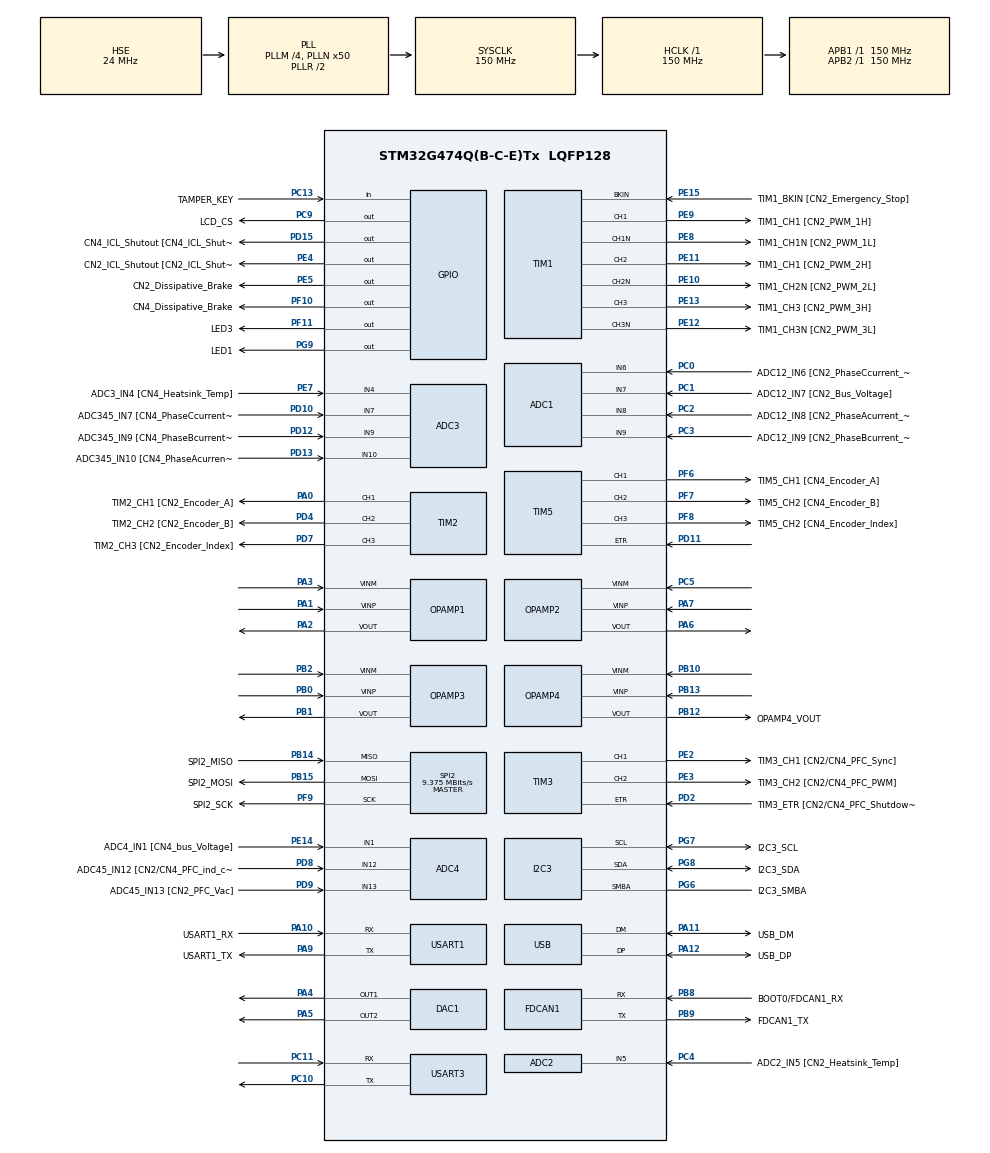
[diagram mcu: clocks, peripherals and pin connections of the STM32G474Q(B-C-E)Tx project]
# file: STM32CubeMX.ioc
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ADC1.Channel-7\#ChannelRegularConversion=ADC_CHANNEL_7
ADC1.NbrOfConversionFlag=1
ADC1.OffsetNumber-7\#ChannelRegularConversion=ADC_OFFSET_NONE
ADC1.Rank-7\#ChannelRegularConversion=1
ADC1.SamplingTime-7\#ChannelRegularConversion=ADC_SAMPLETIME_2CYCLES_5
ADC1.master=1
ADC2.Channel-0\#ChannelRegularConversion=ADC_CHANNEL_5
ADC2.NbrOfConversionFlag=1
ADC2.OffsetNumber-0\#ChannelRegularConversion=ADC_OFFSET_NONE
ADC2.Rank-0\#ChannelRegularConversion=1
ADC2.SamplingTime-0\#ChannelRegularConversion=ADC_SAMPLETIME_2CYCLES_5
ADC3.Channel-0\#ChannelRegularConversion=ADC_CHANNEL_9
ADC3.NbrOfConversionFlag=1
ADC3.OffsetNumber-0\#ChannelRegularConversion=ADC_OFFSET_NONE
ADC3.Rank-0\#ChannelRegularConversion=1
ADC3.SamplingTime-0\#ChannelRegularConversion=ADC_SAMPLETIME_2CYCLES_5
ADC3.master=1
ADC4.Channel-0\#ChannelRegularConversion=ADC_CHANNEL_12
ADC4.NbrOfConversionFlag=1
ADC4.OffsetNumber-0\#ChannelRegularConversion=ADC_OFFSET_NONE
ADC4.Rank-0\#ChannelRegularConversion=1
ADC4.SamplingTime-0\#ChannelRegularConversion=ADC_SAMPLETIME_2CYCLES_5
DAC1.DAC_Channel-DAC_OUT2=DAC_CHANNEL_2
FDCAN1.CalculateBaudRateNominal=3125000
FDCAN1.CalculateTimeBitNominal=320
FDCAN1.CalculateTimeQuantumNominal=106.66666666666667
I2C3.Timeout=0x00008727
I2C3.Timing=0x30D293D6
Mcu.Family=STM32G4
Mcu.Name=STM32G474Q(B-C-E)Tx
Mcu.Package=LQFP128
NVIC.PriorityGroup=NVIC_PRIORITYGROUP_4
NVIC.TIM20_UP_IRQn=true\:15\:0\:false\:false\:true\:false\:true\:true
NVIC.TimeBase=TIM20_UP_IRQn
NVIC.TimeBaseIP=TIM20
NVIC.USART1_IRQn=true\:8\:0\:true\:false\:true\:true\:true\:true
NVIC.USART3_IRQn=true\:8\:0\:true\:false\:true\:true\:true\:true
NVIC.USB_HP_IRQn=true\:8\:0\:true\:false\:true\:true\:true\:true
NVIC.USB_LP_IRQn=true\:8\:0\:true\:false\:true\:true\:true\:true
PA0.GPIO_Label=TIM2_CH1 [CN2_Encoder_A]
PA0.Signal=S_TIM2_CH1
PA1.Mode=Standalone
PA1.Signal=OPAMP1_VINP
PA10.GPIO_Label=USART1_RX
PA10.GPIO_Speed=GPIO_SPEED_FREQ_VERY_HIGH
PA10.Mode=Asynchronous
PA10.Signal=USART1_RX
PA11.GPIO_Label=USB_DM
PA11.Mode=Device
PA11.Signal=USB_DM
PA12.GPIO_Label=USB_DP
PA12.Mode=Device
PA12.Signal=USB_DP
PA13.GPIO_Label=JTMS-SWDIO
PA13.Mode=JTAG_5_pins
PA13.Signal=SYS_JTMS-SWDIO
PA14.GPIO_Label=JTCK-SWCLK
PA14.Mode=JTAG_5_pins
PA14.Signal=SYS_JTCK-SWCLK
PA15.Mode=JTAG_5_pins
PA15.Signal=SYS_JTDI
PA2.Mode=Standalone
PA2.Signal=OPAMP1_VOUT
PA3.Mode=Standalone
PA3.Signal=OPAMP1_VINM
PA4.Signal=COMP_DAC11_group
PA5.Signal=COMP_DAC12_group
PA6.Mode=Standalone
PA6.Signal=OPAMP2_VOUT
PA7.Mode=Standalone
PA7.Signal=OPAMP2_VINP
PA9.GPIO_Label=USART1_TX
PA9.GPIO_Speed=GPIO_SPEED_FREQ_VERY_HIGH
PA9.Mode=Asynchronous
PA9.Signal=USART1_TX
PB0.Mode=Standalone
PB0.Signal=OPAMP3_VINP
PB1.Mode=Standalone
PB1.Signal=OPAMP3_VOUT
PB10.Mode=Standalone
PB10.Signal=OPAMP4_VINM
PB12.GPIO_Label=OPAMP4_VOUT
PB12.Mode=Standalone
PB12.Signal=OPAMP4_VOUT
PB13.Mode=Standalone
PB13.Signal=OPAMP4_VINP
PB14.GPIO_Label=SPI2_MISO
PB14.Mode=Full_Duplex_Master
PB14.Signal=SPI2_MISO
PB15.GPIO_Label=SPI2_MOSI
PB15.Mode=Full_Duplex_Master
PB15.Signal=SPI2_MOSI
PB2.Mode=Standalone
PB2.Signal=OPAMP3_VINM
PB3.GPIO_Label=JTDO-SWO
PB3.Mode=JTAG_5_pins
PB3.Signal=SYS_JTDO-SWO
PB4.GPIO_Label=JTRST/PD_CC2
PB4.Mode=JTAG_5_pins
PB4.Signal=SYS_JTRST
PB8-BOOT0.GPIO_Label=BOOT0/FDCAN1_RX
PB8-BOOT0.Mode=FDCAN_Activate
PB8-BOOT0.Signal=FDCAN1_RX
PB9.GPIO_Label=FDCAN1_TX
PB9.Mode=FDCAN_Activate
PB9.Signal=FDCAN1_TX
PC0.GPIO_Label=ADC12_IN6 [CN2_PhaseCcurrent_plus]
PC0.Signal=SharedAnalog_PC0
PC1.GPIO_Label=ADC12_IN7 [CN2_Bus_Voltage]
PC1.Signal=SharedAnalog_PC1
PC10.GPIO_Speed=GPIO_SPEED_FREQ_VERY_HIGH
PC10.Mode=Asynchronous
PC10.Signal=USART3_TX
PC11.GPIO_Speed=GPIO_SPEED_FREQ_VERY_HIGH
PC11.Mode=Asynchronous
PC11.Signal=USART3_RX
PC13.GPIO_Label=TAMPER_KEY
PC13.Signal=GPIO_Input
PC14-OSC32_IN.GPIO_Label=PC14-OSC32_IN
PC14-OSC32_IN.Mode=LSE-External-Oscillator
PC14-OSC32_IN.Signal=RCC_OSC32_IN
PC15-OSC32_OUT.GPIO_Label=PC15-OSC32_OUT
PC15-OSC32_OUT.Mode=LSE-External-Oscillator
PC15-OSC32_OUT.Signal=RCC_OSC32_OUT
PC2.GPIO_Label=ADC12_IN8 [CN2_PhaseAcurrent_plus]
PC2.Signal=SharedAnalog_PC2
PC3.GPIO_Label=ADC12_IN9 [CN2_PhaseBcurrent_plus]
PC3.Signal=SharedAnalog_PC3
PC4.GPIO_Label=ADC2_IN5 [CN2_Heatsink_Temp]
PC4.Mode=IN5-Single-Ended
PC4.Signal=ADC2_IN5
PC5.Mode=Standalone
PC5.Signal=OPAMP2_VINM
PC9.GPIO_Label=LCD_CS
PC9.Signal=GPIO_Output
PD10.GPIO_Label=ADC345_IN7 [CN4_PhaseCcurrent_plus]
PD10.Signal=SharedAnalog_PD10
PD11.Signal=S_TIM5_ETR
PD12.GPIO_Label=ADC345_IN9 [CN4_PhaseBcurrent_plus]
PD12.Signal=SharedAnalog_PD12
PD13.GPIO_Label=ADC345_IN10 [CN4_PhaseAcurrent_plus]
PD13.Signal=SharedAnalog_PD13
PD15.GPIO_Label=CN4_ICL_Shutout [CN4_ICL_Shutout]
PD15.Signal=GPIO_Output
PD2.GPIO_Label=TIM3_ETR [CN2/CN4_PFC_Shutdown]
PD2.Signal=S_TIM3_ETR
PD4.GPIO_Label=TIM2_CH2 [CN2_Encoder_B]
PD4.Signal=S_TIM2_CH2
PD7.GPIO_Label=TIM2_CH3 [CN2_Encoder_Index]
PD7.Signal=S_TIM2_CH3
PD8.GPIO_Label=ADC45_IN12 [CN2/CN4_PFC_ind_current]
PD8.Signal=SharedAnalog_PD8
PD9.GPIO_Label=ADC45_IN13 [CN2_PFC_Vac]
PD9.Signal=SharedAnalog_PD9
PE10.GPIO_Label=TIM1_CH2N [CN2_PWM_2L]
PE10.Mode=Output Compare2 CH2 CH2N
PE10.Signal=TIM1_CH2N
PE11.GPIO_Label=TIM1_CH1 [CN2_PWM_2H]
PE11.Signal=S_TIM1_CH2
PE12.GPIO_Label=TIM1_CH3N [CN2_PWM_3L]
PE12.Mode=Output Compare3 CH3 CH3N
PE12.Signal=TIM1_CH3N
PE13.GPIO_Label=TIM1_CH3 [CN2_PWM_3H]
PE13.Signal=S_TIM1_CH3
PE14.GPIO_Label=ADC4_IN1 [CN4_bus_Voltage]
PE14.Mode=IN1-Single-Ended
PE14.Signal=ADC4_IN1
PE15.GPIO_Label=TIM1_BKIN [CN2_Emergency_Stop]
PE15.Mode=Activate-Break-Input
PE15.Signal=TIM1_BKIN
PE2.GPIO_Label=TIM3_CH1 [CN2/CN4_PFC_Sync]
PE2.Signal=S_TIM3_CH1
PE3.GPIO_Label=TIM3_CH2 [CN2/CN4_PFC_PWM]
PE3.Signal=S_TIM3_CH2
PE4.GPIO_Label=CN2_ICL_Shutout [CN2_ICL_Shutout]
PE4.Signal=GPIO_Output
PE5.GPIO_Label=CN2_Dissipative_Brake
PE5.Signal=GPIO_Output
PE7.GPIO_Label=ADC3_IN4 [CN4_Heatsink_Temp]
PE7.Mode=IN4-Single-Ended
PE7.Signal=ADC3_IN4
PE8.GPIO_Label=TIM1_CH1N [CN2_PWM_1L]
PE8.Mode=Output Compare1 CH1 CH1N
PE8.Signal=TIM1_CH1N
PE9.GPIO_Label=TIM1_CH1 [CN2_PWM_1H]
PE9.Signal=S_TIM1_CH1
PF0-OSC_IN.GPIO_Label=PF0-OSC_IN
PF0-OSC_IN.Mode=HSE-External-Oscillator
PF0-OSC_IN.Signal=RCC_OSC_IN
PF1-OSC_OUT.GPIO_Label=PF1-OSC_OUT
PF1-OSC_OUT.Mode=HSE-External-Oscillator
PF1-OSC_OUT.Signal=RCC_OSC_OUT
PF10.GPIO_Label=CN4_Dissipative_Brake
PF10.Signal=GPIO_Output
PF11.GPIO_Label=LED3
PF11.Signal=GPIO_Output
PF6.GPIO_Label=TIM5_CH1 [CN4_Encoder_A]
PF6.Signal=S_TIM5_CH1
PF7.GPIO_Label=TIM5_CH2 [CN4_Encoder_B]
PF7.Signal=S_TIM5_CH2
PF8.GPIO_Label=TIM5_CH2 [CN4_Encoder_Index]
PF8.Signal=S_TIM5_CH3
PF9.GPIO_Label=SPI2_SCK
PF9.Mode=Full_Duplex_Master
PF9.Signal=SPI2_SCK
PG6.GPIO_Label=I2C3_SMBA
PG6.GPIO_Pu=GPIO_PULLUP
PG6.Mode=SMBus-Alert-mode
PG6.Signal=I2C3_SMBA
PG7.GPIO_Label=I2C3_SCL
PG7.GPIO_Pu=GPIO_PULLUP
PG7.Mode=SMBus-Alert-mode
PG7.Signal=I2C3_SCL
PG8.GPIO_Label=I2C3_SDA
PG8.GPIO_Pu=GPIO_PULLUP
PG8.Mode=SMBus-Alert-mode
PG8.Signal=I2C3_SDA
PG9.GPIO_Label=LED1
PG9.Signal=GPIO_Output
ProjectManager.HeapSize=0x10000
ProjectManager.StackSize=0x400
ProjectManager.TargetToolchain=STM32CubeIDE
RCC.ADC12Freq_Value=150000000
RCC.ADC345Freq_Value=150000000
RCC.AHBFreq_Value=150000000
RCC.APB1Freq_Value=150000000
RCC.APB1TimFreq_Value=150000000
RCC.APB2Freq_Value=150000000
RCC.APB2TimFreq_Value=150000000
RCC.CK48CLockSelection=RCC_USBCLKSOURCE_HSI48
RCC.CortexFreq_Value=150000000
RCC.EXTERNAL_CLOCK_VALUE=12288000
RCC.HCLKFreq_Value=150000000
RCC.HSE_VALUE=24000000
RCC.HSI48_VALUE=48000000
RCC.HSI_VALUE=16000000
RCC.PLLM=RCC_PLLM_DIV4
RCC.PLLN=50
RCC.PLLSourceVirtual=RCC_PLLSOURCE_HSE
RCC.SYSCLKFreq_VALUE=150000000
RCC.SYSCLKSource=RCC_SYSCLKSOURCE_PLLCLK
RCC.USBFreq_Value=48000000
RCC.VCOOutputFreq_Value=300000000
SH.COMP_DAC11_group.0=DAC1_OUT1,DAC_OUT1
SH.COMP_DAC12_group.0=DAC1_OUT2,DAC_OUT2
SH.S_TIM1_CH1.0=TIM1_CH1,Output Compare1 CH1 CH1N
SH.S_TIM1_CH2.0=TIM1_CH2,Output Compare2 CH2 CH2N
SH.S_TIM1_CH3.0=TIM1_CH3,Output Compare3 CH3 CH3N
SH.S_TIM2_CH1.0=TIM2_CH1,Output Compare1 CH1
SH.S_TIM2_CH2.0=TIM2_CH2,Output Compare2 CH2
SH.S_TIM2_CH3.0=TIM2_CH3,Output Compare3 CH3
SH.S_TIM3_CH1.0=TIM3_CH1,Output Compare1 CH1
SH.S_TIM3_CH2.0=TIM3_CH2,Output Compare2 CH2
SH.S_TIM3_ETR.0=TIM3_ETR,ETR-as-clearing-source
SH.S_TIM5_CH1.0=TIM5_CH1,Output Compare1 CH1
SH.S_TIM5_CH2.0=TIM5_CH2,Output Compare2 CH2
SH.S_TIM5_CH3.0=TIM5_CH3,Output Compare3 CH3
SH.S_TIM5_ETR.0=TIM5_ETR,ETR-as-clearing-source
SH.SharedAnalog_PC0.0=ADC2_IN6
SH.SharedAnalog_PC0.1=ADC1_IN6,IN6-Single-Ended
SH.SharedAnalog_PC1.0=ADC2_IN7
SH.SharedAnalog_PC1.1=ADC1_IN7,IN7-Single-Ended
SH.SharedAnalog_PC2.0=ADC2_IN8
SH.SharedAnalog_PC2.1=ADC1_IN8,IN8-Single-Ended
SH.SharedAnalog_PC3.0=ADC2_IN9
SH.SharedAnalog_PC3.1=ADC1_IN9,IN9-Single-Ended
SH.SharedAnalog_PD10.0=ADC4_IN7
SH.SharedAnalog_PD10.1=ADC5_IN7
SH.SharedAnalog_PD10.2=ADC3_IN7,IN7-Single-Ended
SH.SharedAnalog_PD12.0=ADC4_IN9
SH.SharedAnalog_PD12.1=ADC5_IN9
SH.SharedAnalog_PD12.2=ADC3_IN9,IN9-Single-Ended
SH.SharedAnalog_PD13.0=ADC4_IN10
SH.SharedAnalog_PD13.1=ADC5_IN10
SH.SharedAnalog_PD13.2=ADC3_IN10,IN10-Single-Ended
SH.SharedAnalog_PD8.0=ADC5_IN12
SH.SharedAnalog_PD8.1=ADC4_IN12,IN12-Single-Ended
SH.SharedAnalog_PD9.0=ADC5_IN13
SH.SharedAnalog_PD9.1=ADC4_IN13,IN13-Single-Ended
SPI2.BaudRatePrescaler=SPI_BAUDRATEPRESCALER_16
SPI2.CalculateBaudRate=9.375 MBits/s
SPI2.Direction=SPI_DIRECTION_2LINES
SPI2.Mode=SPI_MODE_MASTER
SPI2.VirtualType=VM_MASTER
TIM1.Channel-Output\ Compare1\ CH1\ CH1N=TIM_CHANNEL_1
TIM1.Channel-Output\ Compare2\ CH2\ CH2N=TIM_CHANNEL_2
TIM1.Channel-Output\ Compare3\ CH3\ CH3N=TIM_CHANNEL_3
TIM2.Channel-Output\ Compare1\ CH1=TIM_CHANNEL_1
TIM2.Channel-Output\ Compare2\ CH2=TIM_CHANNEL_2
TIM2.Channel-Output\ Compare3\ CH3=TIM_CHANNEL_3
TIM3.Channel-Output\ Compare1\ CH1=TIM_CHANNEL_1
TIM3.Channel-Output\ Compare2\ CH2=TIM_CHANNEL_2
TIM5.Channel-Output\ Compare1\ CH1=TIM_CHANNEL_1
TIM5.Channel-Output\ Compare2\ CH2=TIM_CHANNEL_2
TIM5.Channel-Output\ Compare3\ CH3=TIM_CHANNEL_3
USART1.VirtualMode-Asynchronous=VM_ASYNC
USART1.WordLength=WORDLENGTH_7B
USART3.VirtualMode-Asynchronous=VM_ASYNC
VP_HRTIM1_VS_hrtimMasterTimerNoOutput.Mode=MasterTimer
VP_SYS_VS_DBSignals.Mode=DisableDeadBatterySignals
VP_SYS_VS_tim20.Mode=TIM20
board=STM32G474E-EVAL1

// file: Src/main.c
/* USER CODE BEGIN Header */
/**
  ******************************************************************************
  * @file           : main.c
  * @brief          : Main program body
  ******************************************************************************
  * @attention
  *
  * Copyright (c) 2024 STMicroelectronics.
  * All rights reserved.
  *
  * This software is licensed under terms that can be found in the LICENSE file
  * in the root directory of this software component.
  * If no LICENSE file comes with this software, it is provided AS-IS.
  *
  ******************************************************************************
  */
/* USER CODE END Header */
#include "main.h"

/* USER CODE BEGIN Includes */
#include "cmsis_vio.h"
/* USER CODE END Includes */

ADC_HandleTypeDef hadc1;
ADC_HandleTypeDef hadc2;
ADC_HandleTypeDef hadc3;
ADC_HandleTypeDef hadc4;

DAC_HandleTypeDef hdac1;

FDCAN_HandleTypeDef hfdcan1;

HRTIM_HandleTypeDef hhrtim1;

SMBUS_HandleTypeDef hsmbus3;

OPAMP_HandleTypeDef hopamp1;
OPAMP_HandleTypeDef hopamp2;
OPAMP_HandleTypeDef hopamp3;
OPAMP_HandleTypeDef hopamp4;

SPI_HandleTypeDef hspi2;

TIM_HandleTypeDef htim1;
TIM_HandleTypeDef htim2;
TIM_HandleTypeDef htim3;
TIM_HandleTypeDef htim5;

UART_HandleTypeDef huart1;
UART_HandleTypeDef huart3;

PCD_HandleTypeDef hpcd_USB_FS;

void SystemClock_Config(void);
static void MX_GPIO_Init(void);
static void MX_ADC1_Init(void);
static void MX_ADC2_Init(void);
static void MX_ADC3_Init(void);
static void MX_ADC4_Init(void);
static void MX_DAC1_Init(void);
static void MX_FDCAN1_Init(void);
static void MX_HRTIM1_Init(void);
static void MX_I2C3_SMBUS_Init(void);
static void MX_OPAMP1_Init(void);
static void MX_OPAMP2_Init(void);
static void MX_OPAMP3_Init(void);
static void MX_OPAMP4_Init(void);
static void MX_SPI2_Init(void);
static void MX_TIM1_Init(void);
static void MX_TIM2_Init(void);
static void MX_TIM3_Init(void);
static void MX_TIM5_Init(void);
static void MX_USART1_UART_Init(void);
static void MX_USB_PCD_Init(void);
static void MX_USART3_UART_Init(void);

int main(void)
{

  /* MCU Configuration--------------------------------------------------------*/

  /* Reset of all peripherals, Initializes the Flash interface and the Systick. */
  HAL_Init();

  /* Configure the system clock */
  SystemClock_Config();

  /* USER CODE BEGIN SysInit */
  SystemCoreClockUpdate();
  /* USER CODE END SysInit */

  /* Initialize all configured peripherals */
  MX_GPIO_Init();
  MX_ADC1_Init();
  MX_ADC2_Init();
  MX_ADC3_Init();
  MX_ADC4_Init();
  MX_DAC1_Init();
  MX_FDCAN1_Init();
  MX_HRTIM1_Init();
  MX_I2C3_SMBUS_Init();
  MX_OPAMP1_Init();
  MX_OPAMP2_Init();
  MX_OPAMP3_Init();
  MX_OPAMP4_Init();
  MX_SPI2_Init();
  MX_TIM1_Init();
  MX_TIM2_Init();
  MX_TIM3_Init();
  MX_TIM5_Init();
  MX_USART1_UART_Init();
  MX_USB_PCD_Init();
  MX_USART3_UART_Init();
  /* USER CODE BEGIN 2 */

  stdio_init();                         /* Initialize STDIO */

  vioInit();                            /* Initialize Virtual I/O */

#ifdef CMSIS_shield_header
  shield_setup();                       /* Setup Shield */
#endif

  app_main();                           /* Execute Application main */

  /* USER CODE END 2 */

  /* Infinite loop */
  while (1)
  {

  }
}

void SystemClock_Config(void)
{
  RCC_OscInitTypeDef RCC_OscInitStruct = {0};
  RCC_ClkInitTypeDef RCC_ClkInitStruct = {0};

  /** Configure the main internal regulator output voltage
  */
  HAL_PWREx_ControlVoltageScaling(PWR_REGULATOR_VOLTAGE_SCALE1);

  /** Initializes the RCC Oscillators according to the specified parameters
  * in the RCC_OscInitTypeDef structure.
  */
  RCC_OscInitStruct.OscillatorType = RCC_OSCILLATORTYPE_HSI48|RCC_OSCILLATORTYPE_HSE;
  RCC_OscInitStruct.HSEState = RCC_HSE_ON;
  RCC_OscInitStruct.HSI48State = RCC_HSI48_ON;
  RCC_OscInitStruct.PLL.PLLState = RCC_PLL_ON;
  RCC_OscInitStruct.PLL.PLLSource = RCC_PLLSOURCE_HSE;
  RCC_OscInitStruct.PLL.PLLM = RCC_PLLM_DIV4;
  RCC_OscInitStruct.PLL.PLLN = 50;
  RCC_OscInitStruct.PLL.PLLP = RCC_PLLP_DIV2;
  RCC_OscInitStruct.PLL.PLLQ = RCC_PLLQ_DIV2;
  RCC_OscInitStruct.PLL.PLLR = RCC_PLLR_DIV2;
  if (HAL_RCC_OscConfig(&RCC_OscInitStruct) != HAL_OK)
  {
    Error_Handler();
  }

  /** Initializes the CPU, AHB and APB buses clocks
  */
  RCC_ClkInitStruct.ClockType = RCC_CLOCKTYPE_HCLK|RCC_CLOCKTYPE_SYSCLK
                              |RCC_CLOCKTYPE_PCLK1|RCC_CLOCKTYPE_PCLK2;
  RCC_ClkInitStruct.SYSCLKSource = RCC_SYSCLKSOURCE_PLLCLK;
  RCC_ClkInitStruct.AHBCLKDivider = RCC_SYSCLK_DIV1;
  RCC_ClkInitStruct.APB1CLKDivider = RCC_HCLK_DIV1;
  RCC_ClkInitStruct.APB2CLKDivider = RCC_HCLK_DIV1;

  if (HAL_RCC_ClockConfig(&RCC_ClkInitStruct, FLASH_LATENCY_4) != HAL_OK)
  {
    Error_Handler();
  }
}

static void MX_ADC1_Init(void)
{

  ADC_MultiModeTypeDef multimode = {0};
  ADC_ChannelConfTypeDef sConfig = {0};

  /** Common config
  */
  hadc1.Instance = ADC1;
  hadc1.Init.ClockPrescaler = ADC_CLOCK_SYNC_PCLK_DIV4;
  hadc1.Init.Resolution = ADC_RESOLUTION_12B;
  hadc1.Init.DataAlign = ADC_DATAALIGN_RIGHT;
  hadc1.Init.GainCompensation = 0;
  hadc1.Init.ScanConvMode = ADC_SCAN_DISABLE;
  hadc1.Init.EOCSelection = ADC_EOC_SINGLE_CONV;
  hadc1.Init.LowPowerAutoWait = DISABLE;
  hadc1.Init.ContinuousConvMode = DISABLE;
  hadc1.Init.NbrOfConversion = 1;
  hadc1.Init.DiscontinuousConvMode = DISABLE;
  hadc1.Init.ExternalTrigConv = ADC_SOFTWARE_START;
  hadc1.Init.ExternalTrigConvEdge = ADC_EXTERNALTRIGCONVEDGE_NONE;
  hadc1.Init.DMAContinuousRequests = DISABLE;
  hadc1.Init.Overrun = ADC_OVR_DATA_PRESERVED;
  hadc1.Init.OversamplingMode = DISABLE;
  if (HAL_ADC_Init(&hadc1) != HAL_OK)
  {
    Error_Handler();
  }

  /** Configure the ADC multi-mode
  */
  multimode.Mode = ADC_MODE_INDEPENDENT;
  if (HAL_ADCEx_MultiModeConfigChannel(&hadc1, &multimode) != HAL_OK)
  {
    Error_Handler();
  }

  /** Configure Regular Channel
  */
  sConfig.Channel = ADC_CHANNEL_7;
  sConfig.Rank = ADC_REGULAR_RANK_1;
  sConfig.SamplingTime = ADC_SAMPLETIME_2CYCLES_5;
  sConfig.SingleDiff = ADC_SINGLE_ENDED;
  sConfig.OffsetNumber = ADC_OFFSET_NONE;
  sConfig.Offset = 0;
  if (HAL_ADC_ConfigChannel(&hadc1, &sConfig) != HAL_OK)
  {
    Error_Handler();
  }

}

static void MX_ADC2_Init(void)
{

  ADC_ChannelConfTypeDef sConfig = {0};

  /** Common config
  */
  hadc2.Instance = ADC2;
  hadc2.Init.ClockPrescaler = ADC_CLOCK_SYNC_PCLK_DIV4;
  hadc2.Init.Resolution = ADC_RESOLUTION_12B;
  hadc2.Init.DataAlign = ADC_DATAALIGN_RIGHT;
  hadc2.Init.GainCompensation = 0;
  hadc2.Init.ScanConvMode = ADC_SCAN_DISABLE;
  hadc2.Init.EOCSelection = ADC_EOC_SINGLE_CONV;
  hadc2.Init.LowPowerAutoWait = DISABLE;
  hadc2.Init.ContinuousConvMode = DISABLE;
  hadc2.Init.NbrOfConversion = 1;
  hadc2.Init.DiscontinuousConvMode = DISABLE;
  hadc2.Init.ExternalTrigConv = ADC_SOFTWARE_START;
  hadc2.Init.ExternalTrigConvEdge = ADC_EXTERNALTRIGCONVEDGE_NONE;
  hadc2.Init.DMAContinuousRequests = DISABLE;
  hadc2.Init.Overrun = ADC_OVR_DATA_PRESERVED;
  hadc2.Init.OversamplingMode = DISABLE;
  if (HAL_ADC_Init(&hadc2) != HAL_OK)
  {
    Error_Handler();
  }

  /** Configure Regular Channel
  */
  sConfig.Channel = ADC_CHANNEL_5;
  sConfig.Rank = ADC_REGULAR_RANK_1;
  sConfig.SamplingTime = ADC_SAMPLETIME_2CYCLES_5;
  sConfig.SingleDiff = ADC_SINGLE_ENDED;
  sConfig.OffsetNumber = ADC_OFFSET_NONE;
  sConfig.Offset = 0;
  if (HAL_ADC_ConfigChannel(&hadc2, &sConfig) != HAL_OK)
  {
    Error_Handler();
  }

}

static void MX_ADC3_Init(void)
{

  ADC_MultiModeTypeDef multimode = {0};
  ADC_ChannelConfTypeDef sConfig = {0};

  /** Common config
  */
  hadc3.Instance = ADC3;
  hadc3.Init.ClockPrescaler = ADC_CLOCK_SYNC_PCLK_DIV4;
  hadc3.Init.Resolution = ADC_RESOLUTION_12B;
  hadc3.Init.DataAlign = ADC_DATAALIGN_RIGHT;
  hadc3.Init.GainCompensation = 0;
  hadc3.Init.ScanConvMode = ADC_SCAN_DISABLE;
  hadc3.Init.EOCSelection = ADC_EOC_SINGLE_CONV;
  hadc3.Init.LowPowerAutoWait = DISABLE;
  hadc3.Init.ContinuousConvMode = DISABLE;
  hadc3.Init.NbrOfConversion = 1;
  hadc3.Init.DiscontinuousConvMode = DISABLE;
  hadc3.Init.ExternalTrigConv = ADC_SOFTWARE_START;
  hadc3.Init.ExternalTrigConvEdge = ADC_EXTERNALTRIGCONVEDGE_NONE;
  hadc3.Init.DMAContinuousRequests = DISABLE;
  hadc3.Init.Overrun = ADC_OVR_DATA_PRESERVED;
  hadc3.Init.OversamplingMode = DISABLE;
  if (HAL_ADC_Init(&hadc3) != HAL_OK)
  {
    Error_Handler();
  }

  /** Configure the ADC multi-mode
  */
  multimode.Mode = ADC_MODE_INDEPENDENT;
  if (HAL_ADCEx_MultiModeConfigChannel(&hadc3, &multimode) != HAL_OK)
  {
    Error_Handler();
  }

  /** Configure Regular Channel
  */
  sConfig.Channel = ADC_CHANNEL_9;
  sConfig.Rank = ADC_REGULAR_RANK_1;
  sConfig.SamplingTime = ADC_SAMPLETIME_2CYCLES_5;
  sConfig.SingleDiff = ADC_SINGLE_ENDED;
  sConfig.OffsetNumber = ADC_OFFSET_NONE;
  sConfig.Offset = 0;
  if (HAL_ADC_ConfigChannel(&hadc3, &sConfig) != HAL_OK)
  {
    Error_Handler();
  }

}

static void MX_ADC4_Init(void)
{

  ADC_ChannelConfTypeDef sConfig = {0};

  /** Common config
  */
  hadc4.Instance = ADC4;
  hadc4.Init.ClockPrescaler = ADC_CLOCK_SYNC_PCLK_DIV4;
  hadc4.Init.Resolution = ADC_RESOLUTION_12B;
  hadc4.Init.DataAlign = ADC_DATAALIGN_RIGHT;
  hadc4.Init.GainCompensation = 0;
  hadc4.Init.ScanConvMode = ADC_SCAN_DISABLE;
  hadc4.Init.EOCSelection = ADC_EOC_SINGLE_CONV;
  hadc4.Init.LowPowerAutoWait = DISABLE;
  hadc4.Init.ContinuousConvMode = DISABLE;
  hadc4.Init.NbrOfConversion = 1;
  hadc4.Init.DiscontinuousConvMode = DISABLE;
  hadc4.Init.ExternalTrigConv = ADC_SOFTWARE_START;
  hadc4.Init.ExternalTrigConvEdge = ADC_EXTERNALTRIGCONVEDGE_NONE;
  hadc4.Init.DMAContinuousRequests = DISABLE;
  hadc4.Init.Overrun = ADC_OVR_DATA_PRESERVED;
  hadc4.Init.OversamplingMode = DISABLE;
  if (HAL_ADC_Init(&hadc4) != HAL_OK)
  {
    Error_Handler();
  }

  /** Configure Regular Channel
  */
  sConfig.Channel = ADC_CHANNEL_12;
  sConfig.Rank = ADC_REGULAR_RANK_1;
  sConfig.SamplingTime = ADC_SAMPLETIME_2CYCLES_5;
  sConfig.SingleDiff = ADC_SINGLE_ENDED;
  sConfig.OffsetNumber = ADC_OFFSET_NONE;
  sConfig.Offset = 0;
  if (HAL_ADC_ConfigChannel(&hadc4, &sConfig) != HAL_OK)
  {
    Error_Handler();
  }

}

static void MX_DAC1_Init(void)
{

  DAC_ChannelConfTypeDef sConfig = {0};

  /** DAC Initialization
  */
  hdac1.Instance = DAC1;
  if (HAL_DAC_Init(&hdac1) != HAL_OK)
  {
    Error_Handler();
  }

  /** DAC channel OUT1 config
  */
  sConfig.DAC_HighFrequency = DAC_HIGH_FREQUENCY_INTERFACE_MODE_AUTOMATIC;
  sConfig.DAC_DMADoubleDataMode = DISABLE;
  sConfig.DAC_SignedFormat = DISABLE;
  sConfig.DAC_SampleAndHold = DAC_SAMPLEANDHOLD_DISABLE;
  sConfig.DAC_Trigger = DAC_TRIGGER_NONE;
  sConfig.DAC_Trigger2 = DAC_TRIGGER_NONE;
  sConfig.DAC_OutputBuffer = DAC_OUTPUTBUFFER_ENABLE;
  sConfig.DAC_ConnectOnChipPeripheral = DAC_CHIPCONNECT_EXTERNAL;
  sConfig.DAC_UserTrimming = DAC_TRIMMING_FACTORY;
  if (HAL_DAC_ConfigChannel(&hdac1, &sConfig, DAC_CHANNEL_1) != HAL_OK)
  {
    Error_Handler();
  }

  /** DAC channel OUT2 config
  */
  if (HAL_DAC_ConfigChannel(&hdac1, &sConfig, DAC_CHANNEL_2) != HAL_OK)
  {
    Error_Handler();
  }

}

static void MX_FDCAN1_Init(void)
{

  hfdcan1.Instance = FDCAN1;
  hfdcan1.Init.ClockDivider = FDCAN_CLOCK_DIV1;
  hfdcan1.Init.FrameFormat = FDCAN_FRAME_CLASSIC;
  hfdcan1.Init.Mode = FDCAN_MODE_NORMAL;
  hfdcan1.Init.AutoRetransmission = DISABLE;
  hfdcan1.Init.TransmitPause = DISABLE;
  hfdcan1.Init.ProtocolException = DISABLE;
  hfdcan1.Init.NominalPrescaler = 16;
  hfdcan1.Init.NominalSyncJumpWidth = 1;
  hfdcan1.Init.NominalTimeSeg1 = 2;
  hfdcan1.Init.NominalTimeSeg2 = 2;
  hfdcan1.Init.DataPrescaler = 1;
  hfdcan1.Init.DataSyncJumpWidth = 1;
  hfdcan1.Init.DataTimeSeg1 = 1;
  hfdcan1.Init.DataTimeSeg2 = 1;
  hfdcan1.Init.StdFiltersNbr = 0;
  hfdcan1.Init.ExtFiltersNbr = 0;
  hfdcan1.Init.TxFifoQueueMode = FDCAN_TX_FIFO_OPERATION;
  if (HAL_FDCAN_Init(&hfdcan1) != HAL_OK)
  {
    Error_Handler();
  }

}

static void MX_HRTIM1_Init(void)
{

  HRTIM_TimeBaseCfgTypeDef pTimeBaseCfg = {0};
  HRTIM_TimerCfgTypeDef pTimerCfg = {0};

  hhrtim1.Instance = HRTIM1;
  hhrtim1.Init.HRTIMInterruptResquests = HRTIM_IT_NONE;
  hhrtim1.Init.SyncOptions = HRTIM_SYNCOPTION_NONE;
  if (HAL_HRTIM_Init(&hhrtim1) != HAL_OK)
  {
    Error_Handler();
  }
  if (HAL_HRTIM_DLLCalibrationStart(&hhrtim1, HRTIM_CALIBRATIONRATE_3) != HAL_OK)
  {
    Error_Handler();
  }
  if (HAL_HRTIM_PollForDLLCalibration(&hhrtim1, 10) != HAL_OK)
  {
    Error_Handler();
  }
  pTimeBaseCfg.Period = 0xFFDF;
  pTimeBaseCfg.RepetitionCounter = 0x00;
  pTimeBaseCfg.PrescalerRatio = HRTIM_PRESCALERRATIO_MUL32;
  pTimeBaseCfg.Mode = HRTIM_MODE_CONTINUOUS;
  if (HAL_HRTIM_TimeBaseConfig(&hhrtim1, HRTIM_TIMERINDEX_MASTER, &pTimeBaseCfg) != HAL_OK)
  {
    Error_Handler();
  }
  pTimerCfg.InterruptRequests = HRTIM_MASTER_IT_NONE;
  pTimerCfg.DMARequests = HRTIM_MASTER_DMA_NONE;
  pTimerCfg.DMASrcAddress = 0x0000;
  pTimerCfg.DMADstAddress = 0x0000;
  pTimerCfg.DMASize = 0x1;
  pTimerCfg.HalfModeEnable = HRTIM_HALFMODE_DISABLED;
  pTimerCfg.InterleavedMode = HRTIM_INTERLEAVED_MODE_DISABLED;
  pTimerCfg.StartOnSync = HRTIM_SYNCSTART_DISABLED;
  pTimerCfg.ResetOnSync = HRTIM_SYNCRESET_DISABLED;
  pTimerCfg.DACSynchro = HRTIM_DACSYNC_NONE;
  pTimerCfg.PreloadEnable = HRTIM_PRELOAD_DISABLED;
  pTimerCfg.UpdateGating = HRTIM_UPDATEGATING_INDEPENDENT;
  pTimerCfg.BurstMode = HRTIM_TIMERBURSTMODE_MAINTAINCLOCK;
  pTimerCfg.RepetitionUpdate = HRTIM_UPDATEONREPETITION_DISABLED;
  pTimerCfg.ReSyncUpdate = HRTIM_TIMERESYNC_UPDATE_UNCONDITIONAL;

  if (HAL_HRTIM_WaveformTimerConfig(&hhrtim1, HRTIM_TIMERINDEX_MASTER, &pTimerCfg) != HAL_OK)
  {
    Error_Handler();
  }

}

static void MX_I2C3_SMBUS_Init(void)
{

  hsmbus3.Instance = I2C3;
  hsmbus3.Init.Timing = 0x30D293D6;
  hsmbus3.Init.AnalogFilter = SMBUS_ANALOGFILTER_ENABLE;
  hsmbus3.Init.OwnAddress1 = 2;
  hsmbus3.Init.AddressingMode = SMBUS_ADDRESSINGMODE_7BIT;
  hsmbus3.Init.DualAddressMode = SMBUS_DUALADDRESS_DISABLE;
  hsmbus3.Init.OwnAddress2 = 0;
  hsmbus3.Init.OwnAddress2Masks = SMBUS_OA2_NOMASK;
  hsmbus3.Init.GeneralCallMode = SMBUS_GENERALCALL_DISABLE;
  hsmbus3.Init.NoStretchMode = SMBUS_NOSTRETCH_DISABLE;
  hsmbus3.Init.PacketErrorCheckMode = SMBUS_PEC_DISABLE;
  hsmbus3.Init.PeripheralMode = SMBUS_PERIPHERAL_MODE_SMBUS_SLAVE;
  hsmbus3.Init.SMBusTimeout = 0x00008727;
  if (HAL_SMBUS_Init(&hsmbus3) != HAL_OK)
  {
    Error_Handler();
  }

  /** configuration Alert Mode
  */
  if (HAL_SMBUS_EnableAlert_IT(&hsmbus3) != HAL_OK)
  {
    Error_Handler();
  }

}

static void MX_OPAMP1_Init(void)
{

  hopamp1.Instance = OPAMP1;
  hopamp1.Init.PowerMode = OPAMP_POWERMODE_NORMALSPEED;
  hopamp1.Init.Mode = OPAMP_STANDALONE_MODE;
  hopamp1.Init.InvertingInput = OPAMP_INVERTINGINPUT_IO0;
  hopamp1.Init.NonInvertingInput = OPAMP_NONINVERTINGINPUT_IO0;
  hopamp1.Init.InternalOutput = DISABLE;
  hopamp1.Init.TimerControlledMuxmode = OPAMP_TIMERCONTROLLEDMUXMODE_DISABLE;
  hopamp1.Init.UserTrimming = OPAMP_TRIMMING_FACTORY;
  if (HAL_OPAMP_Init(&hopamp1) != HAL_OK)
  {
    Error_Handler();
  }

}

static void MX_OPAMP2_Init(void)
{

  hopamp2.Instance = OPAMP2;
  hopamp2.Init.PowerMode = OPAMP_POWERMODE_NORMALSPEED;
  hopamp2.Init.Mode = OPAMP_STANDALONE_MODE;
  hopamp2.Init.InvertingInput = OPAMP_INVERTINGINPUT_IO1;
  hopamp2.Init.NonInvertingInput = OPAMP_NONINVERTINGINPUT_IO0;
  hopamp2.Init.InternalOutput = DISABLE;
  hopamp2.Init.TimerControlledMuxmode = OPAMP_TIMERCONTROLLEDMUXMODE_DISABLE;
  hopamp2.Init.UserTrimming = OPAMP_TRIMMING_FACTORY;
  if (HAL_OPAMP_Init(&hopamp2) != HAL_OK)
  {
    Error_Handler();
  }

}

static void MX_OPAMP3_Init(void)
{

  hopamp3.Instance = OPAMP3;
  hopamp3.Init.PowerMode = OPAMP_POWERMODE_NORMALSPEED;
  hopamp3.Init.Mode = OPAMP_STANDALONE_MODE;
  hopamp3.Init.InvertingInput = OPAMP_INVERTINGINPUT_IO0;
  hopamp3.Init.NonInvertingInput = OPAMP_NONINVERTINGINPUT_IO0;
  hopamp3.Init.InternalOutput = DISABLE;
  hopamp3.Init.TimerControlledMuxmode = OPAMP_TIMERCONTROLLEDMUXMODE_DISABLE;
  hopamp3.Init.UserTrimming = OPAMP_TRIMMING_FACTORY;
  if (HAL_OPAMP_Init(&hopamp3) != HAL_OK)
  {
    Error_Handler();
  }

}

static void MX_OPAMP4_Init(void)
{

  hopamp4.Instance = OPAMP4;
  hopamp4.Init.PowerMode = OPAMP_POWERMODE_NORMALSPEED;
  hopamp4.Init.Mode = OPAMP_STANDALONE_MODE;
  hopamp4.Init.InvertingInput = OPAMP_INVERTINGINPUT_IO0;
  hopamp4.Init.NonInvertingInput = OPAMP_NONINVERTINGINPUT_IO0;
  hopamp4.Init.InternalOutput = DISABLE;
  hopamp4.Init.TimerControlledMuxmode = OPAMP_TIMERCONTROLLEDMUXMODE_DISABLE;
  hopamp4.Init.UserTrimming = OPAMP_TRIMMING_FACTORY;
  if (HAL_OPAMP_Init(&hopamp4) != HAL_OK)
  {
    Error_Handler();
  }

}

static void MX_SPI2_Init(void)
{

  /* SPI2 parameter configuration*/
  hspi2.Instance = SPI2;
  hspi2.Init.Mode = SPI_MODE_MASTER;
  hspi2.Init.Direction = SPI_DIRECTION_2LINES;
  hspi2.Init.DataSize = SPI_DATASIZE_4BIT;
  hspi2.Init.CLKPolarity = SPI_POLARITY_LOW;
  hspi2.Init.CLKPhase = SPI_PHASE_1EDGE;
  hspi2.Init.NSS = SPI_NSS_SOFT;
  hspi2.Init.BaudRatePrescaler = SPI_BAUDRATEPRESCALER_16;
  hspi2.Init.FirstBit = SPI_FIRSTBIT_MSB;
  hspi2.Init.TIMode = SPI_TIMODE_DISABLE;
  hspi2.Init.CRCCalculation = SPI_CRCCALCULATION_DISABLE;
  hspi2.Init.CRCPolynomial = 7;
  hspi2.Init.CRCLength = SPI_CRC_LENGTH_DATASIZE;
  hspi2.Init.NSSPMode = SPI_NSS_PULSE_ENABLE;
  if (HAL_SPI_Init(&hspi2) != HAL_OK)
  {
    Error_Handler();
  }

}

static void MX_TIM1_Init(void)
{

  TIM_MasterConfigTypeDef sMasterConfig = {0};
  TIMEx_BreakInputConfigTypeDef sBreakInputConfig = {0};
  TIM_OC_InitTypeDef sConfigOC = {0};
  TIM_BreakDeadTimeConfigTypeDef sBreakDeadTimeConfig = {0};

  htim1.Instance = TIM1;
  htim1.Init.Prescaler = 0;
  htim1.Init.CounterMode = TIM_COUNTERMODE_UP;
  htim1.Init.Period = 65535;
  htim1.Init.ClockDivision = TIM_CLOCKDIVISION_DIV1;
  htim1.Init.RepetitionCounter = 0;
  htim1.Init.AutoReloadPreload = TIM_AUTORELOAD_PRELOAD_DISABLE;
  if (HAL_TIM_OC_Init(&htim1) != HAL_OK)
  {
    Error_Handler();
  }
  sMasterConfig.MasterOutputTrigger = TIM_TRGO_RESET;
  sMasterConfig.MasterOutputTrigger2 = TIM_TRGO2_RESET;
  sMasterConfig.MasterSlaveMode = TIM_MASTERSLAVEMODE_DISABLE;
  if (HAL_TIMEx_MasterConfigSynchronization(&htim1, &sMasterConfig) != HAL_OK)
  {
    Error_Handler();
  }
  sBreakInputConfig.Source = TIM_BREAKINPUTSOURCE_BKIN;
  sBreakInputConfig.Enable = TIM_BREAKINPUTSOURCE_ENABLE;
  sBreakInputConfig.Polarity = TIM_BREAKINPUTSOURCE_POLARITY_HIGH;
  if (HAL_TIMEx_ConfigBreakInput(&htim1, TIM_BREAKINPUT_BRK, &sBreakInputConfig) != HAL_OK)
  {
    Error_Handler();
  }
  sConfigOC.OCMode = TIM_OCMODE_TIMING;
  sConfigOC.Pulse = 0;
  sConfigOC.OCPolarity = TIM_OCPOLARITY_HIGH;
  sConfigOC.OCNPolarity = TIM_OCNPOLARITY_HIGH;
  sConfigOC.OCFastMode = TIM_OCFAST_DISABLE;
  sConfigOC.OCIdleState = TIM_OCIDLESTATE_RESET;
  sConfigOC.OCNIdleState = TIM_OCNIDLESTATE_RESET;
  if (HAL_TIM_OC_ConfigChannel(&htim1, &sConfigOC, TIM_CHANNEL_1) != HAL_OK)
  {
    Error_Handler();
  }
  if (HAL_TIM_OC_ConfigChannel(&htim1, &sConfigOC, TIM_CHANNEL_2) != HAL_OK)
  {
    Error_Handler();
  }
  if (HAL_TIM_OC_ConfigChannel(&htim1, &sConfigOC, TIM_CHANNEL_3) != HAL_OK)
  {
    Error_Handler();
  }
  sBreakDeadTimeConfig.OffStateRunMode = TIM_OSSR_DISABLE;
  sBreakDeadTimeConfig.OffStateIDLEMode = TIM_OSSI_DISABLE;
  sBreakDeadTimeConfig.LockLevel = TIM_LOCKLEVEL_OFF;
  sBreakDeadTimeConfig.DeadTime = 0;
  sBreakDeadTimeConfig.BreakState = TIM_BREAK_ENABLE;
  sBreakDeadTimeConfig.BreakPolarity = TIM_BREAKPOLARITY_HIGH;
  sBreakDeadTimeConfig.BreakFilter = 0;
  sBreakDeadTimeConfig.BreakAFMode = TIM_BREAK_AFMODE_INPUT;
  sBreakDeadTimeConfig.Break2State = TIM_BREAK2_DISABLE;
  sBreakDeadTimeConfig.Break2Polarity = TIM_BREAK2POLARITY_HIGH;
  sBreakDeadTimeConfig.Break2Filter = 0;
  sBreakDeadTimeConfig.Break2AFMode = TIM_BREAK_AFMODE_INPUT;
  sBreakDeadTimeConfig.AutomaticOutput = TIM_AUTOMATICOUTPUT_DISABLE;
  if (HAL_TIMEx_ConfigBreakDeadTime(&htim1, &sBreakDeadTimeConfig) != HAL_OK)
  {
    Error_Handler();
  }
  HAL_TIM_MspPostInit(&htim1);

}

static void MX_TIM2_Init(void)
{

  TIM_MasterConfigTypeDef sMasterConfig = {0};
  TIM_OC_InitTypeDef sConfigOC = {0};

  htim2.Instance = TIM2;
  htim2.Init.Prescaler = 0;
  htim2.Init.CounterMode = TIM_COUNTERMODE_UP;
  htim2.Init.Period = 4294967295;
  htim2.Init.ClockDivision = TIM_CLOCKDIVISION_DIV1;
  htim2.Init.AutoReloadPreload = TIM_AUTORELOAD_PRELOAD_DISABLE;
  if (HAL_TIM_OC_Init(&htim2) != HAL_OK)
  {
    Error_Handler();
  }
  sMasterConfig.MasterOutputTrigger = TIM_TRGO_RESET;
  sMasterConfig.MasterSlaveMode = TIM_MASTERSLAVEMODE_DISABLE;
  if (HAL_TIMEx_MasterConfigSynchronization(&htim2, &sMasterConfig) != HAL_OK)
  {
    Error_Handler();
  }
  sConfigOC.OCMode = TIM_OCMODE_TIMING;
  sConfigOC.Pulse = 0;
  sConfigOC.OCPolarity = TIM_OCPOLARITY_HIGH;
  sConfigOC.OCFastMode = TIM_OCFAST_DISABLE;
  if (HAL_TIM_OC_ConfigChannel(&htim2, &sConfigOC, TIM_CHANNEL_1) != HAL_OK)
  {
    Error_Handler();
  }
  if (HAL_TIM_OC_ConfigChannel(&htim2, &sConfigOC, TIM_CHANNEL_2) != HAL_OK)
  {
    Error_Handler();
  }
  if (HAL_TIM_OC_ConfigChannel(&htim2, &sConfigOC, TIM_CHANNEL_3) != HAL_OK)
  {
    Error_Handler();
  }
  HAL_TIM_MspPostInit(&htim2);

}

static void MX_TIM3_Init(void)
{

  TIM_MasterConfigTypeDef sMasterConfig = {0};
  TIM_OC_InitTypeDef sConfigOC = {0};

  htim3.Instance = TIM3;
  htim3.Init.Prescaler = 0;
  htim3.Init.CounterMode = TIM_COUNTERMODE_UP;
  htim3.Init.Period = 65535;
  htim3.Init.ClockDivision = TIM_CLOCKDIVISION_DIV1;
  htim3.Init.AutoReloadPreload = TIM_AUTORELOAD_PRELOAD_DISABLE;
  if (HAL_TIM_OC_Init(&htim3) != HAL_OK)
  {
    Error_Handler();
  }
  sMasterConfig.MasterOutputTrigger = TIM_TRGO_RESET;
  sMasterConfig.MasterSlaveMode = TIM_MASTERSLAVEMODE_DISABLE;
  if (HAL_TIMEx_MasterConfigSynchronization(&htim3, &sMasterConfig) != HAL_OK)
  {
    Error_Handler();
  }
  sConfigOC.OCMode = TIM_OCMODE_TIMING;
  sConfigOC.Pulse = 0;
  sConfigOC.OCPolarity = TIM_OCPOLARITY_HIGH;
  sConfigOC.OCFastMode = TIM_OCFAST_DISABLE;
  if (HAL_TIM_OC_ConfigChannel(&htim3, &sConfigOC, TIM_CHANNEL_1) != HAL_OK)
  {
    Error_Handler();
  }
  if (HAL_TIM_OC_ConfigChannel(&htim3, &sConfigOC, TIM_CHANNEL_2) != HAL_OK)
  {
    Error_Handler();
  }
  HAL_TIM_MspPostInit(&htim3);

}

static void MX_TIM5_Init(void)
{

  TIM_MasterConfigTypeDef sMasterConfig = {0};
  TIM_OC_InitTypeDef sConfigOC = {0};

  htim5.Instance = TIM5;
  htim5.Init.Prescaler = 0;
  htim5.Init.CounterMode = TIM_COUNTERMODE_UP;
  htim5.Init.Period = 4294967295;
  htim5.Init.ClockDivision = TIM_CLOCKDIVISION_DIV1;
  htim5.Init.AutoReloadPreload = TIM_AUTORELOAD_PRELOAD_DISABLE;
  if (HAL_TIM_OC_Init(&htim5) != HAL_OK)
  {
    Error_Handler();
  }
  sMasterConfig.MasterOutputTrigger = TIM_TRGO_RESET;
  sMasterConfig.MasterSlaveMode = TIM_MASTERSLAVEMODE_DISABLE;
  if (HAL_TIMEx_MasterConfigSynchronization(&htim5, &sMasterConfig) != HAL_OK)
  {
    Error_Handler();
  }
  sConfigOC.OCMode = TIM_OCMODE_TIMING;
  sConfigOC.Pulse = 0;
  sConfigOC.OCPolarity = TIM_OCPOLARITY_HIGH;
  sConfigOC.OCFastMode = TIM_OCFAST_DISABLE;
  if (HAL_TIM_OC_ConfigChannel(&htim5, &sConfigOC, TIM_CHANNEL_1) != HAL_OK)
  {
    Error_Handler();
  }
  if (HAL_TIM_OC_ConfigChannel(&htim5, &sConfigOC, TIM_CHANNEL_2) != HAL_OK)
  {
    Error_Handler();
  }
  if (HAL_TIM_OC_ConfigChannel(&htim5, &sConfigOC, TIM_CHANNEL_3) != HAL_OK)
  {
    Error_Handler();
  }
  HAL_TIM_MspPostInit(&htim5);

}

static void MX_USART1_UART_Init(void)
{

  huart1.Instance = USART1;
  huart1.Init.BaudRate = 115200;
  huart1.Init.WordLength = UART_WORDLENGTH_7B;
  huart1.Init.StopBits = UART_STOPBITS_1;
  huart1.Init.Parity = UART_PARITY_NONE;
  huart1.Init.Mode = UART_MODE_TX_RX;
  huart1.Init.HwFlowCtl = UART_HWCONTROL_NONE;
  huart1.Init.OverSampling = UART_OVERSAMPLING_16;
  huart1.Init.OneBitSampling = UART_ONE_BIT_SAMPLE_DISABLE;
  huart1.Init.ClockPrescaler = UART_PRESCALER_DIV1;
  huart1.AdvancedInit.AdvFeatureInit = UART_ADVFEATURE_NO_INIT;
  if (HAL_UART_Init(&huart1) != HAL_OK)
  {
    Error_Handler();
  }
  if (HAL_UARTEx_SetTxFifoThreshold(&huart1, UART_TXFIFO_THRESHOLD_1_8) != HAL_OK)
  {
    Error_Handler();
  }
  if (HAL_UARTEx_SetRxFifoThreshold(&huart1, UART_RXFIFO_THRESHOLD_1_8) != HAL_OK)
  {
    Error_Handler();
  }
  if (HAL_UARTEx_DisableFifoMode(&huart1) != HAL_OK)
  {
    Error_Handler();
  }

}

static void MX_USART3_UART_Init(void)
{

  huart3.Instance = USART3;
  huart3.Init.BaudRate = 115200;
  huart3.Init.WordLength = UART_WORDLENGTH_8B;
  huart3.Init.StopBits = UART_STOPBITS_1;
  huart3.Init.Parity = UART_PARITY_NONE;
  huart3.Init.Mode = UART_MODE_TX_RX;
  huart3.Init.HwFlowCtl = UART_HWCONTROL_NONE;
  huart3.Init.OverSampling = UART_OVERSAMPLING_16;
  huart3.Init.OneBitSampling = UART_ONE_BIT_SAMPLE_DISABLE;
  huart3.Init.ClockPrescaler = UART_PRESCALER_DIV1;
  huart3.AdvancedInit.AdvFeatureInit = UART_ADVFEATURE_NO_INIT;
  if (HAL_UART_Init(&huart3) != HAL_OK)
  {
    Error_Handler();
  }
  if (HAL_UARTEx_SetTxFifoThreshold(&huart3, UART_TXFIFO_THRESHOLD_1_8) != HAL_OK)
  {
    Error_Handler();
  }
  if (HAL_UARTEx_SetRxFifoThreshold(&huart3, UART_RXFIFO_THRESHOLD_1_8) != HAL_OK)
  {
    Error_Handler();
  }
  if (HAL_UARTEx_DisableFifoMode(&huart3) != HAL_OK)
  {
    Error_Handler();
  }

}

static void MX_USB_PCD_Init(void)
{

  hpcd_USB_FS.Instance = USB;
  hpcd_USB_FS.Init.dev_endpoints = 8;
  hpcd_USB_FS.Init.speed = PCD_SPEED_FULL;
  hpcd_USB_FS.Init.phy_itface = PCD_PHY_EMBEDDED;
  hpcd_USB_FS.Init.Sof_enable = DISABLE;
  hpcd_USB_FS.Init.low_power_enable = DISABLE;
  hpcd_USB_FS.Init.lpm_enable = DISABLE;
  hpcd_USB_FS.Init.battery_charging_enable = DISABLE;
  if (HAL_PCD_Init(&hpcd_USB_FS) != HAL_OK)
  {
    Error_Handler();
  }

}

static void MX_GPIO_Init(void)
{
  GPIO_InitTypeDef GPIO_InitStruct = {0};

  /* GPIO Ports Clock Enable */
  __HAL_RCC_GPIOE_CLK_ENABLE();
  __HAL_RCC_GPIOC_CLK_ENABLE();
  __HAL_RCC_GPIOF_CLK_ENABLE();
  __HAL_RCC_GPIOA_CLK_ENABLE();
  __HAL_RCC_GPIOB_CLK_ENABLE();
  __HAL_RCC_GPIOD_CLK_ENABLE();
  __HAL_RCC_GPIOG_CLK_ENABLE();

  /*Configure GPIO pin Output Level */
  HAL_GPIO_WritePin(GPIOE, CN2_ICL_Shutout_Pin|CN2_Dissipative_Brake_Pin, GPIO_PIN_RESET);

  /*Configure GPIO pin Output Level */
  HAL_GPIO_WritePin(GPIOF, CN4_Dissipative_Brake_Pin|LED3_Pin, GPIO_PIN_RESET);

  /*Configure GPIO pin Output Level */
  HAL_GPIO_WritePin(CN4_ICL_Shutout_GPIO_Port, CN4_ICL_Shutout_Pin, GPIO_PIN_RESET);

  /*Configure GPIO pin Output Level */
  HAL_GPIO_WritePin(LCD_CS_GPIO_Port, LCD_CS_Pin, GPIO_PIN_RESET);

  /*Configure GPIO pin Output Level */
  HAL_GPIO_WritePin(LED1_GPIO_Port, LED1_Pin, GPIO_PIN_RESET);

  /*Configure GPIO pins : CN2_ICL_Shutout_Pin CN2_Dissipative_Brake_Pin */
  GPIO_InitStruct.Pin = CN2_ICL_Shutout_Pin|CN2_Dissipative_Brake_Pin;
  GPIO_InitStruct.Mode = GPIO_MODE_OUTPUT_PP;
  GPIO_InitStruct.Pull = GPIO_NOPULL;
  GPIO_InitStruct.Speed = GPIO_SPEED_FREQ_LOW;
  HAL_GPIO_Init(GPIOE, &GPIO_InitStruct);

  /*Configure GPIO pin : TAMPER_KEY_Pin */
  GPIO_InitStruct.Pin = TAMPER_KEY_Pin;
  GPIO_InitStruct.Mode = GPIO_MODE_INPUT;
  GPIO_InitStruct.Pull = GPIO_NOPULL;
  HAL_GPIO_Init(TAMPER_KEY_GPIO_Port, &GPIO_InitStruct);

  /*Configure GPIO pins : CN4_Dissipative_Brake_Pin LED3_Pin */
  GPIO_InitStruct.Pin = CN4_Dissipative_Brake_Pin|LED3_Pin;
  GPIO_InitStruct.Mode = GPIO_MODE_OUTPUT_PP;
  GPIO_InitStruct.Pull = GPIO_NOPULL;
  GPIO_InitStruct.Speed = GPIO_SPEED_FREQ_LOW;
  HAL_GPIO_Init(GPIOF, &GPIO_InitStruct);

  /*Configure GPIO pins : ADC45_IN12_Pin ADC45_IN13_Pin ADC345_IN7_Pin ADC345_IN9_Pin
                           ADC345_IN10_Pin */
  GPIO_InitStruct.Pin = ADC45_IN12_Pin|ADC45_IN13_Pin|ADC345_IN7_Pin|ADC345_IN9_Pin
                          |ADC345_IN10_Pin;
  GPIO_InitStruct.Mode = GPIO_MODE_ANALOG;
  GPIO_InitStruct.Pull = GPIO_NOPULL;
  HAL_GPIO_Init(GPIOD, &GPIO_InitStruct);

  /*Configure GPIO pin : CN4_ICL_Shutout_Pin */
  GPIO_InitStruct.Pin = CN4_ICL_Shutout_Pin;
  GPIO_InitStruct.Mode = GPIO_MODE_OUTPUT_PP;
  GPIO_InitStruct.Pull = GPIO_NOPULL;
  GPIO_InitStruct.Speed = GPIO_SPEED_FREQ_LOW;
  HAL_GPIO_Init(CN4_ICL_Shutout_GPIO_Port, &GPIO_InitStruct);

  /*Configure GPIO pin : LCD_CS_Pin */
  GPIO_InitStruct.Pin = LCD_CS_Pin;
  GPIO_InitStruct.Mode = GPIO_MODE_OUTPUT_PP;
  GPIO_InitStruct.Pull = GPIO_NOPULL;
  GPIO_InitStruct.Speed = GPIO_SPEED_FREQ_LOW;
  HAL_GPIO_Init(LCD_CS_GPIO_Port, &GPIO_InitStruct);

  /*Configure GPIO pin : LED1_Pin */
  GPIO_InitStruct.Pin = LED1_Pin;
  GPIO_InitStruct.Mode = GPIO_MODE_OUTPUT_PP;
  GPIO_InitStruct.Pull = GPIO_NOPULL;
  GPIO_InitStruct.Speed = GPIO_SPEED_FREQ_LOW;
  HAL_GPIO_Init(LED1_GPIO_Port, &GPIO_InitStruct);

}

void HAL_TIM_PeriodElapsedCallback(TIM_HandleTypeDef *htim)
{
  if (htim->Instance == TIM20) {
    HAL_IncTick();
  }
}

void Error_Handler(void)
{
  __disable_irq();
  while (1)
  {
  }
}
